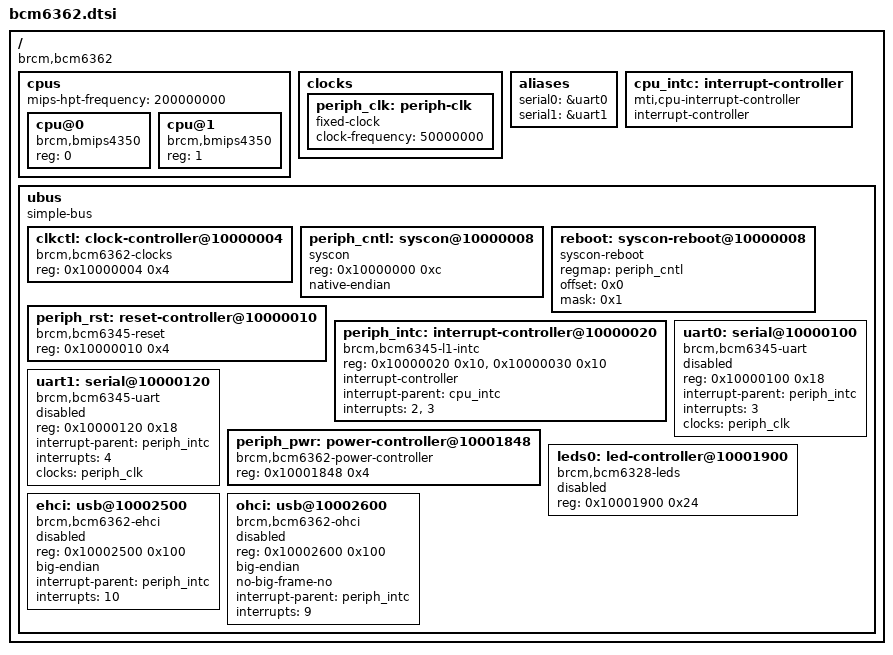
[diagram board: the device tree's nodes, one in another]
// SPDX-License-Identifier: GPL-2.0
/ {
	#address-cells = <1>;
	#size-cells = <1>;
	compatible = "brcm,bcm6362";

	cpus {
		#address-cells = <1>;
		#size-cells = <0>;

		mips-hpt-frequency = <200000000>;

		cpu@0 {
			compatible = "brcm,bmips4350";
			device_type = "cpu";
			reg = <0>;
		};

		cpu@1 {
			compatible = "brcm,bmips4350";
			device_type = "cpu";
			reg = <1>;
		};
	};

	clocks {
		periph_clk: periph-clk {
			compatible = "fixed-clock";
			#clock-cells = <0>;
			clock-frequency = <50000000>;
		};
	};

	aliases {
		serial0 = &uart0;
		serial1 = &uart1;
	};

	cpu_intc: interrupt-controller {
		#address-cells = <0>;
		compatible = "mti,cpu-interrupt-controller";

		interrupt-controller;
		#interrupt-cells = <1>;
	};

	ubus {
		#address-cells = <1>;
		#size-cells = <1>;

		compatible = "simple-bus";
		ranges;

		clkctl: clock-controller@10000004 {
			compatible = "brcm,bcm6362-clocks";
			reg = <0x10000004 0x4>;
			#clock-cells = <1>;
		};

		periph_cntl: syscon@10000008 {
			compatible = "syscon";
			reg = <0x10000000 0xc>;
			native-endian;
		};

		reboot: syscon-reboot@10000008 {
			compatible = "syscon-reboot";
			regmap = <&periph_cntl>;
			offset = <0x0>;
			mask = <0x1>;
		};

		periph_rst: reset-controller@10000010 {
			compatible = "brcm,bcm6345-reset";
			reg = <0x10000010 0x4>;
			#reset-cells = <1>;
		};

		periph_intc: interrupt-controller@10000020 {
			compatible = "brcm,bcm6345-l1-intc";
			reg = <0x10000020 0x10>,
			      <0x10000030 0x10>;

			interrupt-controller;
			#interrupt-cells = <1>;

			interrupt-parent = <&cpu_intc>;
			interrupts = <2>, <3>;
		};

		uart0: serial@10000100 {
			compatible = "brcm,bcm6345-uart";
			reg = <0x10000100 0x18>;

			interrupt-parent = <&periph_intc>;
			interrupts = <3>;

			clocks = <&periph_clk>;
			clock-names = "refclk";

			status = "disabled";
		};

		uart1: serial@10000120 {
			compatible = "brcm,bcm6345-uart";
			reg = <0x10000120 0x18>;

			interrupt-parent = <&periph_intc>;
			interrupts = <4>;

			clocks = <&periph_clk>;
			clock-names = "refclk";

			status = "disabled";
		};

		periph_pwr: power-controller@10001848 {
			compatible = "brcm,bcm6362-power-controller";
			reg = <0x10001848 0x4>;
			#power-domain-cells = <1>;
		};

		leds0: led-controller@10001900 {
			#address-cells = <1>;
			#size-cells = <0>;
			compatible = "brcm,bcm6328-leds";
			reg = <0x10001900 0x24>;

			status = "disabled";
		};

		ehci: usb@10002500 {
			compatible = "brcm,bcm6362-ehci", "generic-ehci";
			reg = <0x10002500 0x100>;
			big-endian;

			interrupt-parent = <&periph_intc>;
			interrupts = <10>;

			status = "disabled";
		};

		ohci: usb@10002600 {
			compatible = "brcm,bcm6362-ohci", "generic-ohci";
			reg = <0x10002600 0x100>;
			big-endian;
			no-big-frame-no;

			interrupt-parent = <&periph_intc>;
			interrupts = <9>;

			status = "disabled";
		};
	};
};
